# STM32F030C6T6 register map
File version: 1.0
STM32F030C6T6,STM32F030C8T6,STM32F030CCT6,STM32F030F4P6,STM32F030K6T6,STM32F030R8T6,STM32F030RCT6,STM32F070C6T6,STM32F070CBT6,STM32F070F6P6,STM32F070RBT6
Registers are 32-bit, access not given, reset 0x0 unless marked. A register's access mark holds for its fields unless they carry their own. Offsets are from the block's base; lines under a group give offsets from that group; [hi:lo] are bit positions; {n}, {i} and the like mark numbered series; 'fields as' and 'values as' point back to an identical list; <NAME> marks a mode.

## Memory map
0x40000400 TIM3
0x40001000 TIM6
0x40001400 TIM7
0x40002000 TIM14
0x40002800 RTC
0x40002C00 WWDG
0x40003000 IWDG
0x40003800 SPI2
0x40004400 USART2
0x40004800 USART3
0x40004C00 USART4
0x40005000 USART5
0x40005400 I2C1
0x40005800 I2C2
0x40005C00 USB
0x40006000 USB
0x40006000 SRAM
0x40007000 PWR
0x40010000 SYSCFG
0x40010400 EXTI
0x40011400 USART6
0x40012400 ADC
0x40012C00 TIM1
0x40013000 SPI1
0x40013800 USART1
0x40014000 TIM15
0x40014400 TIM16
0x40014800 TIM17
0x40020000 DMA
0x40021000 RCC
0x40022000 FLASH
0x40023000 CRC
0x48000000 GPIOA
0x48000400 GPIOB
0x48000800 GPIOC
0x48000C00 GPIOD
0x48001400 GPIOF

## TIM3
Base 0x40000400
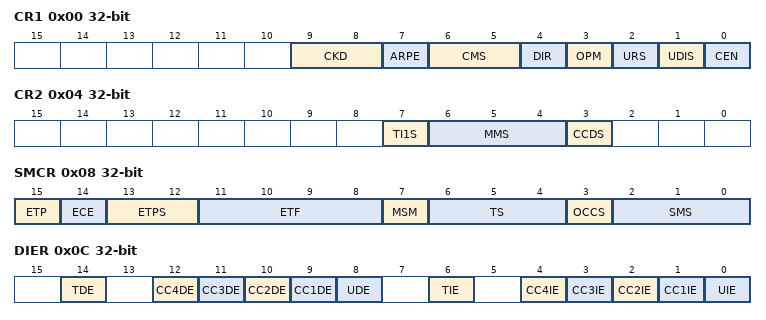
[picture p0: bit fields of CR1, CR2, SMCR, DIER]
0x00 CR1
  [9:8] CKD, [7] ARPE, [6:5] CMS, [4] DIR, [3] OPM, [2] URS, [1] UDIS, [0] CEN
0x04 CR2
  [7] TI1S, [6:4] MMS, [3] CCDS
0x08 SMCR
  [15] ETP, [14] ECE, [13:12] ETPS, [11:8] ETF, [7] MSM, [6:4] TS, [3] OCCS, [2:0] SMS
0x0C DIER
  [14] TDE, [n+8] CC{n}DE (n=1..4), [8] UDE, [6] TIE, [n] CC{n}IE (n=1..4), [0] UIE
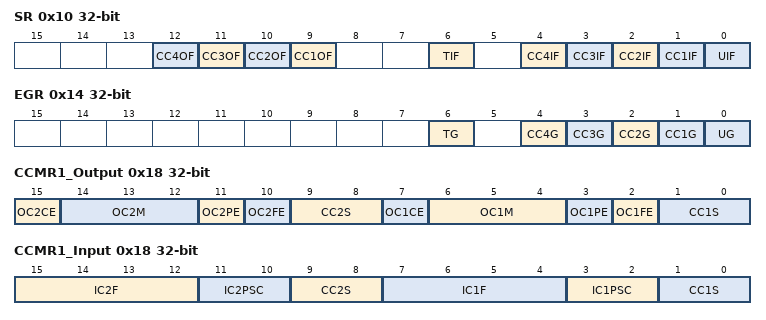
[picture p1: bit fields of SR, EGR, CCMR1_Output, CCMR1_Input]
0x10 SR
  [n+8] CC{n}OF (n=1..4), [6] TIF, [n] CC{n}IF (n=1..4), [0] UIF
0x14 EGR
  [6] TG, [n] CC{n}G (n=1..4), [0] UG
0x18 CCMR1_Output
  [15] OC2CE, [14:12] OC2M, [11] OC2PE, [10] OC2FE, [9:8] CC2S, [7] OC1CE, [6:4] OC1M, [3] OC1PE, [2] OC1FE, [1:0] CC1S
0x18 CCMR1_Input
  [15:12] IC2F, [11:10] IC2PSC, [9:8] CC2S, [7:4] IC1F, [3:2] IC1PSC, [1:0] CC1S
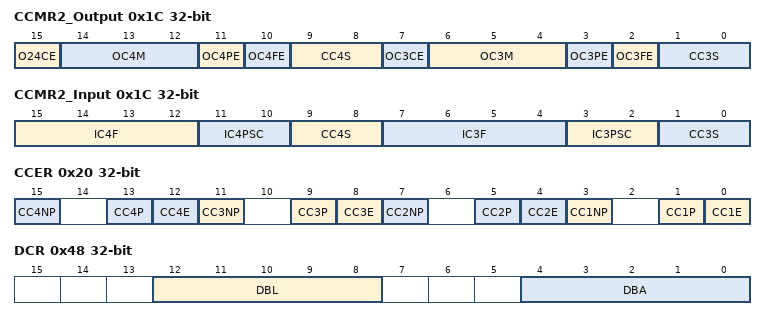
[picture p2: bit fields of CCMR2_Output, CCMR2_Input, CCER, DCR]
0x1C CCMR2_Output
  [15] O24CE, [14:12] OC4M, [11] OC4PE, [10] OC4FE, [9:8] CC4S, [7] OC3CE, [6:4] OC3M, [3] OC3PE, [2] OC3FE, [1:0] CC3S
0x1C CCMR2_Input
  [15:12] IC4F, [11:10] IC4PSC, [9:8] CC4S, [7:4] IC3F, [3:2] IC3PSC, [1:0] CC3S
0x20 CCER
  [4n-1] CC{n}NP (n=1..4), [4n-3] CC{n}P (n=1..4), [4n-4] CC{n}E (n=1..4)
0x24 CNT
  [15:0] CNT
0x28 PSC
  [15:0] PSC
0x2C ARR
  [15:0] ARR
0x40 CCR1
  [15:0] CCR4
0x48 DCR
  [12:8] DBL, [4:0] DBA
0x4C DMAR
  [15:0] DMAB

## TIM1
Base 0x40012C00
Registers as TIM3, without CCR1; these are added or differ:
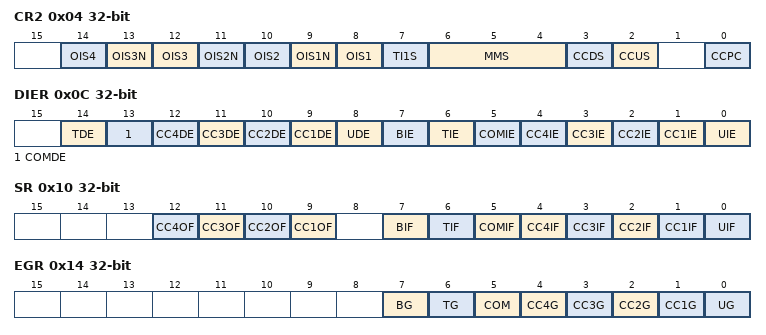
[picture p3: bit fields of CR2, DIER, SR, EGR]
0x04 CR2
  [2n+6] OIS{n} (n=1..4), [13] OIS3N, [11] OIS2N, [9] OIS1N, [7] TI1S, [6:4] MMS, [3] CCDS, [2] CCUS, [0] CCPC
0x0C DIER
  [14] TDE, [13] COMDE, [n+8] CC{n}DE (n=1..4), [8] UDE, [7] BIE, [6] TIE, [5] COMIE, [n] CC{n}IE (n=1..4), [0] UIE
0x10 SR
  [n+8] CC{n}OF (n=1..4), [7] BIF, [6] TIF, [5] COMIF, [n] CC{n}IF (n=1..4), [0] UIF
0x14 EGR
  [7] BG, [6] TG, [5] COM, [n] CC{n}G (n=1..4), [0] UG
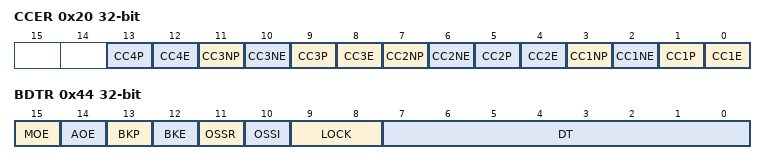
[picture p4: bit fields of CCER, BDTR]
0x20 CCER
  [4n-3] CC{n}P (n=1..4), [4n-4] CC{n}E (n=1..4), [11] CC3NP, [10] CC3NE, [7] CC2NP, [6] CC2NE, [3] CC1NP, [2] CC1NE
0x30 RCR
  [7:0] REP
{0x30+4i} CCR{i} (i=1..4)
  [15:0] CCR{i}
0x44 BDTR
  [15] MOE, [14] AOE, [13] BKP, [12] BKE, [11] OSSR, [10] OSSI, [9:8] LOCK, [7:0] DT

## TIM6
Base 0x40001000
Same registers: TIM7 0x40001400
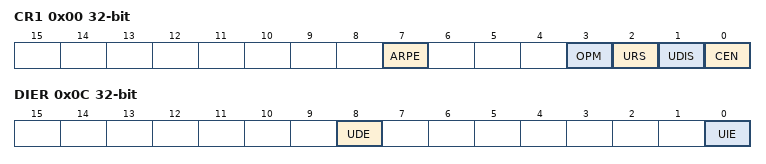
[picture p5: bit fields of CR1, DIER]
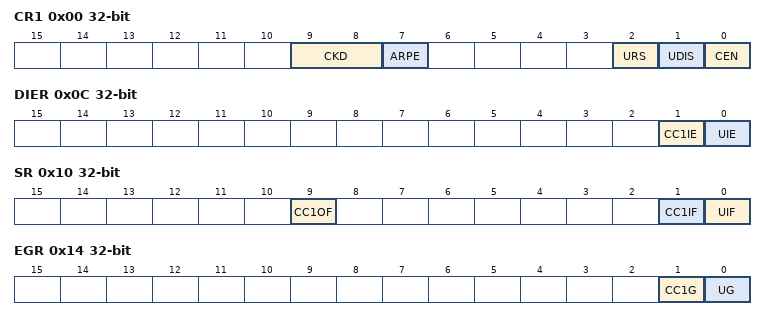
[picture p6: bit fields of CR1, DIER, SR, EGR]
0x00 CR1
  [7] ARPE, [3] OPM, [2] URS, [1] UDIS, [0] CEN
0x0C DIER
  [8] UDE, [0] UIE
0x10 SR
  [0] UIF
0x14 EGR
  [0] UG
0x24 CNT
  [15:0] CNT
0x28 PSC
  [15:0] PSC
0x2C ARR
  [15:0] ARR

## TIM14
Base 0x40002000
0x00 CR1
  [9:8] CKD, [7] ARPE, [2] URS, [1] UDIS, [0] CEN
0x0C DIER
  [1] CC1IE, [0] UIE
0x10 SR
  [9] CC1OF, [1] CC1IF, [0] UIF
0x14 EGR
  [1] CC1G, [0] UG
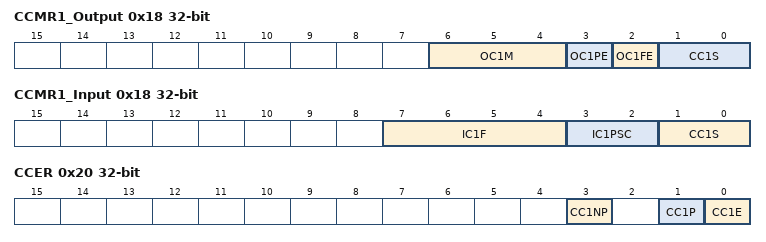
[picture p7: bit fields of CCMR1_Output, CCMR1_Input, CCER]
0x18 CCMR1_Output
  [6:4] OC1M, [3] OC1PE, [2] OC1FE, [1:0] CC1S
0x18 CCMR1_Input
  [7:4] IC1F, [3:2] IC1PSC, [1:0] CC1S
0x20 CCER
  [3] CC1NP, [1] CC1P, [0] CC1E
0x24 CNT
  [15:0] CNT
0x28 PSC
  [15:0] PSC
0x2C ARR
  [15:0] ARR
0x34 CCR1
  [15:0] CCR1
0x50 OR
  [1:0] TI1_RMP

## RTC
Base 0x40002800
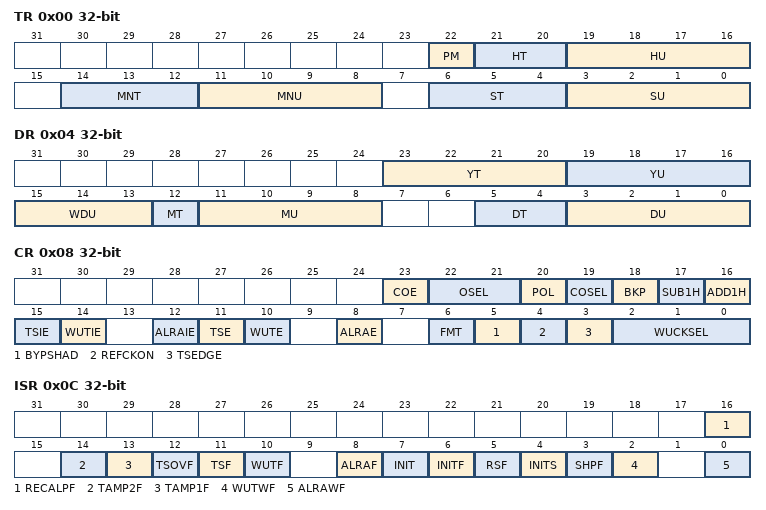
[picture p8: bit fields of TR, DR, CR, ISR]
0x00 TR
  [22] PM, [21:20] HT, [19:16] HU, [14:12] MNT, [11:8] MNU, [6:4] ST, [3:0] SU
0x04 DR
  [23:20] YT, [19:16] YU, [15:13] WDU, [12] MT, [11:8] MU, [5:4] DT, [3:0] DU
0x08 CR
  [23] COE, [22:21] OSEL, [20] POL, [19] COSEL, [18] BKP, [17] SUB1H, [16] ADD1H, [15] TSIE, [14] WUTIE, [12] ALRAIE, [11] TSE, [10] WUTE, [8] ALRAE, [6] FMT, [5] BYPSHAD, [4] REFCKON, [3] TSEDGE, [2:0] WUCKSEL
0x0C ISR
  [16] RECALPF, [14] TAMP2F, [13] TAMP1F, [12] TSOVF, [11] TSF, [10] WUTF, [8] ALRAF, [7] INIT, [6] INITF, [5] RSF, [4] INITS, [3] SHPF, [2] WUTWF, [0] ALRAWF
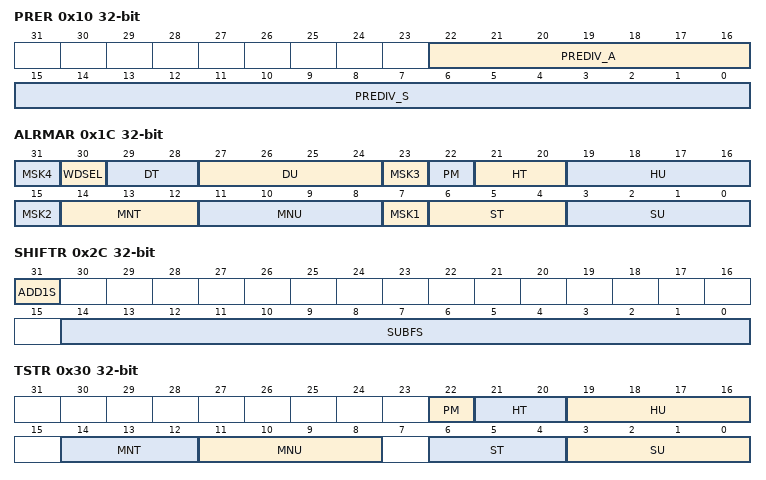
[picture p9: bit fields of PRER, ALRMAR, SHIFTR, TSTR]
0x10 PRER
  [22:16] PREDIV_A, [15:0] PREDIV_S
0x14 WUTR
  [15:0] WUT
0x1C ALRMAR
  [8n-1] MSK{n} (n=1..4), [30] WDSEL, [29:28] DT, [27:24] DU, [22] PM, [21:20] HT, [19:16] HU, [14:12] MNT, [11:8] MNU, [6:4] ST, [3:0] SU
0x24 WPR
  [7:0] KEY
0x28 SSR
  [15:0] SS
0x2C SHIFTR
  [31] ADD1S, [14:0] SUBFS
0x30 TSTR
  fields as TR
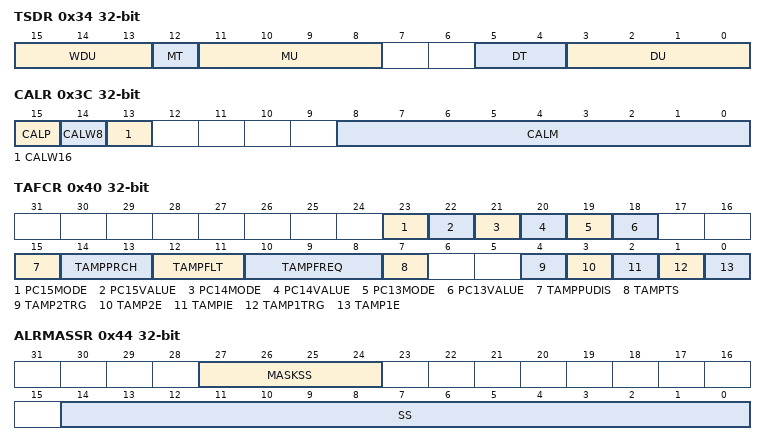
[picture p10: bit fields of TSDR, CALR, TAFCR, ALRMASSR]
0x34 TSDR
  [15:13] WDU, [12] MT, [11:8] MU, [5:4] DT, [3:0] DU
0x38 TSSSR
  [15:0] SS
0x3C CALR
  [15] CALP, [14] CALW8, [13] CALW16, [8:0] CALM
0x40 TAFCR
  [23] PC15MODE, [22] PC15VALUE, [21] PC14MODE, [20] PC14VALUE, [19] PC13MODE, [18] PC13VALUE, [15] TAMPPUDIS, [14:13] TAMPPRCH, [12:11] TAMPFLT, [10:8] TAMPFREQ, [7] TAMPTS, [4] TAMP2TRG, [3] TAMP2E, [2] TAMPIE, [1] TAMP1TRG, [0] TAMP1E
0x44 ALRMASSR
  [27:24] MASKSS, [14:0] SS
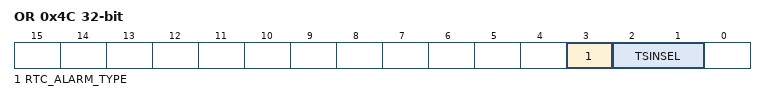
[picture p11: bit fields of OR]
0x4C OR
  [3] RTC_ALARM_TYPE, [2:1] TSINSEL
